# MB9BF52xT register map
File version: 1.0
Registers are 32-bit, read-write, reset 0x0 unless marked. A register's access mark holds for its fields unless they carry their own. Offsets are from the block's base; [hi:lo] are bit positions; {n}, {i} and the like mark numbered series; 'fields as' and 'values as' point back to an identical list.

## BTIOSEL03 — peripheral BTIOSEL03
Base 0x40025100
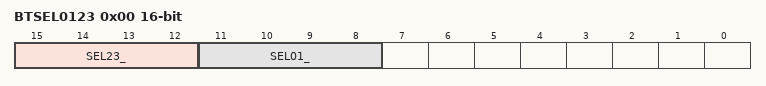
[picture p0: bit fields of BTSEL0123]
0x00 BTSEL0123 16-bit
  [15:12] SEL23_, [11:8] SEL01_

## BTIOSEL47 — peripheral BTIOSEL47
Base 0x40025300
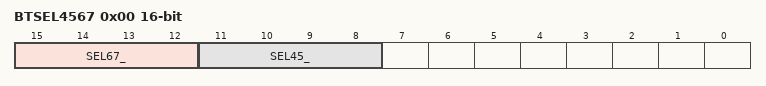
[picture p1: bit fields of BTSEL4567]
0x00 BTSEL4567 16-bit
  [15:12] SEL67_, [11:8] SEL45_

## BTIOSEL8B — peripheral BTIOSEL8B
Base 0x40025500
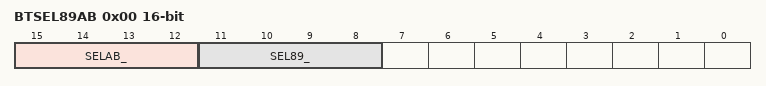
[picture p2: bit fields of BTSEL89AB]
0x00 BTSEL89AB 16-bit
  [15:12] SELAB_, [11:8] SEL89_

## BTIOSELCF — peripheral BTIOSELCF
Base 0x40025700
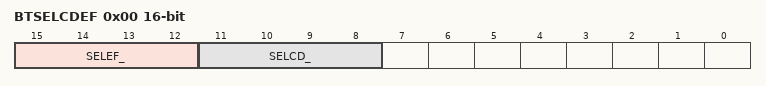
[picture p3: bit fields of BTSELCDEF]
0x00 BTSELCDEF 16-bit
  [15:12] SELEF_, [11:8] SELCD_

## SBSSR — peripheral SBSSR
Base 0x40025F00
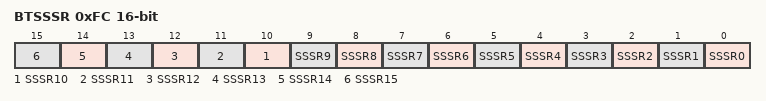
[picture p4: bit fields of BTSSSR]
0xFC BTSSSR 16-bit wo reset not defined
  [n] SSSR{n} (n=0..15)

## BT0 — peripheral BT0
Base 0x40025000
Same registers: BT1 0x40025040, BT2 0x40025080, BT3 0x400250C0, BT4 0x40025200, BT5 0x40025240, BT6 0x40025280, BT7 0x400252C0, BT8 0x40025400, BT9 0x40025440, BT10 0x40025480, BT11 0x400254C0, BT12 0x40025600, BT13 0x40025640, BT14 0x40025680, BT15 0x400256C0
0x00 PWM_PCSR 16-bit reset not defined (PWM view)
0x00 PPG_PRLL 16-bit reset not defined (PPG view)
0x00 RT_PCSR 16-bit reset not defined (RT view)
0x04 PWM_PDUT 16-bit reset not defined (PWM view)
0x04 PPG_PRLH 16-bit reset not defined (PPG view)
0x04 PWC_DTBF 16-bit ro (PWC view)
0x08 PWM_TMR 16-bit ro (PWM view)
0x08 PPG_TMR 16-bit ro (PPG view)
0x08 RT_TMR 16-bit ro reset not defined (RT view)
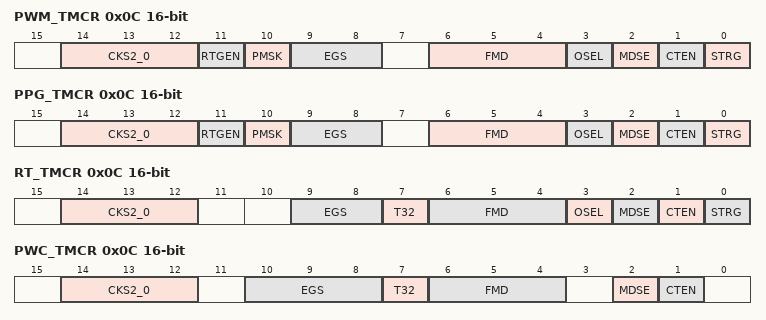
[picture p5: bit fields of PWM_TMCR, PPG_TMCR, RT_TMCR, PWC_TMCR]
0x0C PWM_TMCR 16-bit (PWM view)
  [14:12] CKS2_0, [11] RTGEN, [10] PMSK, [9:8] EGS, [6:4] FMD, [3] OSEL, [2] MDSE, [1] CTEN, [0] STRG
0x0C PPG_TMCR 16-bit (PPG view)
  fields as PWM_TMCR
0x0C RT_TMCR 16-bit (RT view)
  [14:12] CKS2_0, [9:8] EGS, [7] T32, [6:4] FMD, [3] OSEL, [2] MDSE, [1] CTEN, [0] STRG
0x0C PWC_TMCR 16-bit (PWC view)
  [14:12] CKS2_0, [10:8] EGS, [7] T32, [6:4] FMD, [2] MDSE, [1] CTEN
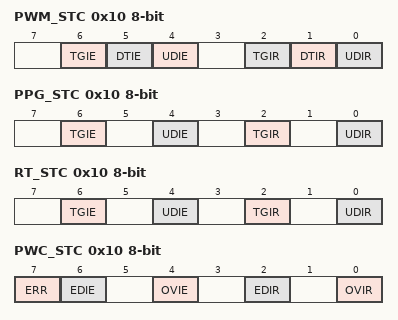
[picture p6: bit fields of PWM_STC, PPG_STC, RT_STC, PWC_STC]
0x10 PWM_STC 8-bit (PWM view)
  [6] TGIE, [5] DTIE, [4] UDIE, [2] TGIR, [1] DTIR, [0] UDIR
0x10 PPG_STC 8-bit (PPG view)
  [6] TGIE, [4] UDIE, [2] TGIR, [0] UDIR
0x10 RT_STC 8-bit (RT view)
  [6] TGIE, [4] UDIE, [2] TGIR, [0] UDIR
0x10 PWC_STC 8-bit (PWC view)
  [7] ERR ro, [6] EDIE, [4] OVIE, [2] EDIR ro, [0] OVIR
0x11 PWM_TMCR2 8-bit (PWM view)
  [0] CKS3
0x11 PPG_TMCR2 8-bit (reset mask 0x1) (PPG view)
  [1] CKS3
0x11 RT_TMCR2 8-bit (RT view)
  [0] CKS3
0x11 PWC_TMCR2 8-bit (PWC view)
  [0] CKS3

## QPRC0 — peripheral QPRC0
Base 0x40026000
Same registers: QPRC1 0x40026040
0x00 QPCR 16-bit
0x04 QRCR 16-bit
0x08 QPCCR 16-bit
0x0C QPRCR 16-bit
0x10 QMPR 16-bit reset 0xFFFF
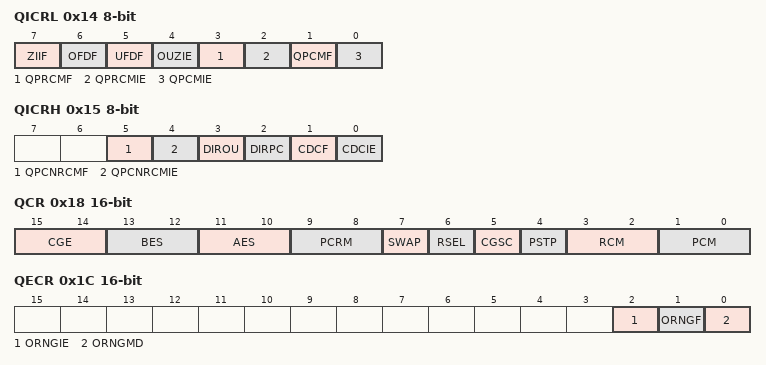
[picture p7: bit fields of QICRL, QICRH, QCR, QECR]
0x14 QICRL 8-bit
  [7] ZIIF, [6] OFDF, [5] UFDF, [4] OUZIE, [3] QPRCMF, [2] QPRCMIE, [1] QPCMF, [0] QPCMIE
0x15 QICRH 8-bit
  [5] QPCNRCMF, [4] QPCNRCMIE, [3] DIROU ro, [2] DIRPC ro, [1] CDCF, [0] CDCIE
0x18 QCR 16-bit
  [15:14] CGE, [13:12] BES, [11:10] AES, [9:8] PCRM, [7] SWAP, [6] RSEL, [5] CGSC, [4] PSTP, [3:2] RCM, [1:0] PCM
0x1C QECR 16-bit
  [2] ORNGIE, [1] ORNGF, [0] ORNGMD
0x3C QRCRR 16-bit
0x3E QPCRR 16-bit

## WC — peripheral WC
Base 0x4003A000
0x00 WCRD 8-bit ro
  [5:0] CTR
0x01 WCRL 8-bit
  [5:0] RLC
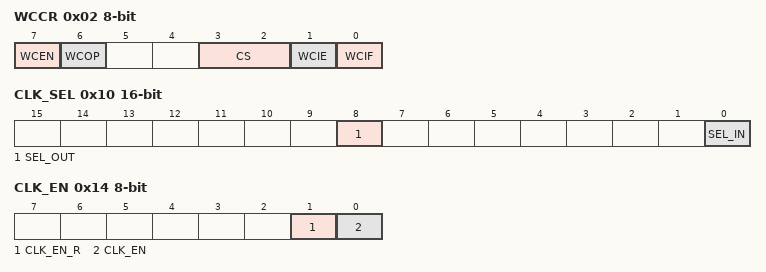
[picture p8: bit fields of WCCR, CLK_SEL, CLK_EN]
0x02 WCCR 8-bit
  [7] WCEN, [6] WCOP ro, [3:2] CS, [1] WCIE, [0] WCIF
0x10 CLK_SEL 16-bit
  [8] SEL_OUT, [0] SEL_IN
0x14 CLK_EN 8-bit
  [1] CLK_EN_R, [0] CLK_EN

## MFT_PPG — peripheral MFT_PPG
Base 0x40024000
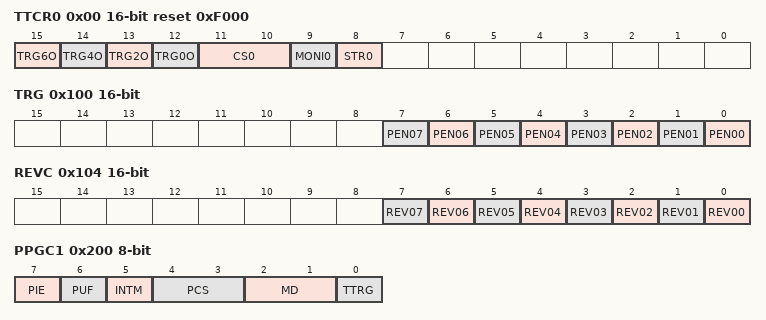
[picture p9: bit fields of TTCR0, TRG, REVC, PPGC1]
0x00 TTCR0 16-bit reset 0xF000
  [15] TRG6O, [14] TRG4O, [13] TRG2O, [12] TRG0O, [11:10] CS0, [9] MONI0 ro, [8] STR0
0x08 COMP0 16-bit (reset mask 0xFF00)
0x0C COMP2 8-bit
0x10 COMP4 16-bit (reset mask 0xFF00)
0x14 COMP6 8-bit
0x100 TRG 16-bit
  [n] PEN{n:02} (n=0..7)
0x104 REVC 16-bit
  [n] REV{n:02} (n=0..7)
0x200 PPGC1 8-bit
  [7] PIE, [6] PUF, [5] INTM, [4:3] PCS, [2:1] MD, [0] TTRG
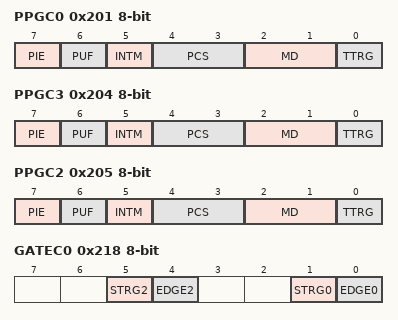
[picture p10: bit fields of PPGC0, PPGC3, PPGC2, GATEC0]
0x201 PPGC0 8-bit
  [7] PIE, [6] PUF, [5] INTM, [4:3] PCS, [2:1] MD, [0] TTRG
0x204 PPGC3 8-bit
  [7] PIE, [6] PUF, [5] INTM, [4:3] PCS, [2:1] MD, [0] TTRG
0x205 PPGC2 8-bit
  [7] PIE, [6] PUF, [5] INTM, [4:3] PCS, [2:1] MD, [0] TTRG
{0x208+4i} PRLL{i} 8-bit reset not defined (i=0..3)
  [7:0] PRLL
{0x209+4i} PRLH{i} 8-bit reset not defined (i=0..3)
  [7:0] PRLH
0x218 GATEC0 8-bit
  [5] STRG2, [4] EDGE2, [1] STRG0, [0] EDGE0
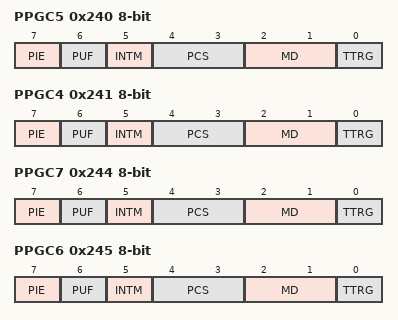
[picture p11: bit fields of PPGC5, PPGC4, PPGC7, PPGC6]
0x240 PPGC5 8-bit
  [7] PIE, [6] PUF, [5] INTM, [4:3] PCS, [2:1] MD, [0] TTRG
0x241 PPGC4 8-bit
  [7] PIE, [6] PUF, [5] INTM, [4:3] PCS, [2:1] MD, [0] TTRG
0x244 PPGC7 8-bit
  [7] PIE, [6] PUF, [5] INTM, [4:3] PCS, [2:1] MD, [0] TTRG
0x245 PPGC6 8-bit
  [7] PIE, [6] PUF, [5] INTM, [4:3] PCS, [2:1] MD, [0] TTRG
{0x238+4i} PRLL{i} 8-bit reset not defined (i=4..7)
  [7:0] PRLL
{0x239+4i} PRLH{i} 8-bit reset not defined (i=4..7)
  [7:0] PRLH
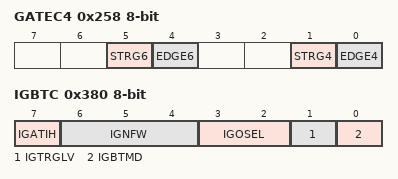
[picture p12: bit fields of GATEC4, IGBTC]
0x258 GATEC4 8-bit
  [5] STRG6, [4] EDGE6, [1] STRG4, [0] EDGE4
0x380 IGBTC 8-bit
  [7] IGATIH, [6:4] IGNFW, [3:2] IGOSEL, [1] IGTRGLV, [0] IGBTMD
